# STM32U366 register map
File version: 1.0
CPU: CM33 r0p1, little endian, MPU, FPU, 4 interrupt priority bits
Registers are 32-bit, read-write, reset 0x0 unless marked. A register's access mark holds for its fields unless they carry their own. Offsets are from the block's base; [hi:lo] are bit positions; 'fields as' and 'values as' point back to an identical list.

## LPUART — LPUART address block description
Base 0x40042400
Same registers: SEC_LPUART 0x50042400
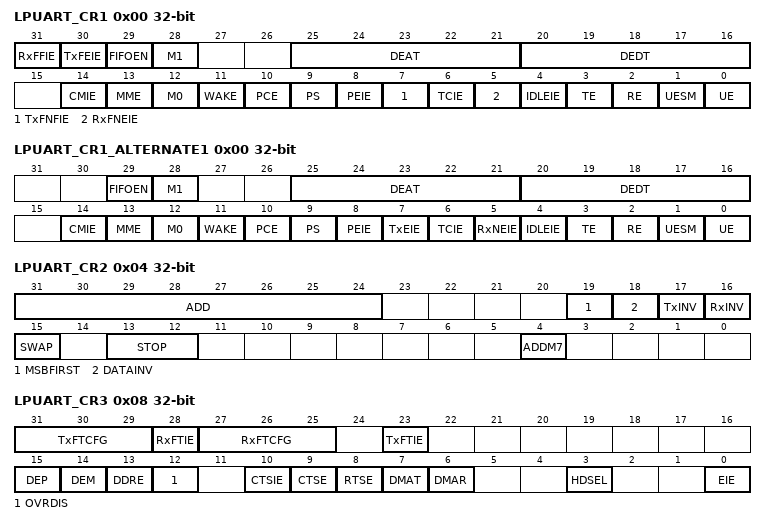
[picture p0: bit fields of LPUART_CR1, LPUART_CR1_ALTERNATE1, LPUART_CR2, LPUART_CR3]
0x00 LPUART_CR1 — LPUART control register 1
  [31] RxFFIE — RxFIFO Full interrupt enable
    0=Interrupt is inhibited; 1=An LPUART interrupt is generated when RxFF=1 in the LPUART_ISR register
  [30] TxFEIE — TxFIFO empty interrupt enable
    0=Interrupt is inhibited; 1=An LPUART interrupt is generated when TxFE=1 in the LPUART_ISR register
  [29] FIFOEN — FIFO mode enable
    0=FIFO mode is disabled; 1=FIFO mode is enabled
  [28] M1 — Word length
  [25:21] DEAT — Driver Enable assertion time
  [20:16] DEDT — Driver Enable deassertion time
  [14] CMIE — Character match interrupt enable
    0=Interrupt is inhibited; 1=A LPUART interrupt is generated when the CMF bit is set in the LPUART_ISR register
  [13] MME — Mute mode enable
    0=Receiver in active mode permanently; 1=Receiver can switch between mute mode and active mode
  [12] M0 — Word length
  [11] WAKE — Receiver wake-up method
    0=Idle line; 1=Address mark
  [10] PCE — Parity control enable
    0=Parity control disabled; 1=Parity control enabled
  [9] PS — Parity selection
    0=Even parity; 1=Odd parity
  [8] PEIE — PE interrupt enable
    0=Interrupt is inhibited; 1=An LPUART interrupt is generated whenever PE=1 in the LPUART_ISR register
  [7] TxFNFIE — TxFIFO not full interrupt enable
    0=Interrupt is inhibited; 1=A LPUART interrupt is generated whenever TxFNF =1 in the LPUART_ISR register
  [6] TCIE — Transmission complete interrupt enable
    0=Interrupt is inhibited; 1=An LPUART interrupt is generated whenever TC=1 in the LPUART_ISR register
  [5] RxFNEIE — RxFIFO not empty interrupt enable
    0=Interrupt is inhibited; 1=A LPUART interrupt is generated whenever ORE=1 or RxFNE=1 in the LPUART_ISR register
  [4] IDLEIE — IDLE interrupt enable
    0=Interrupt is inhibited; 1=An LPUART interrupt is generated whenever IDLE=1 in the LPUART_ISR register
  [3] TE — Transmitter enable
    0=Transmitter is disabled; 1=Transmitter is enabled
  [2] RE — Receiver enable
    0=Receiver is disabled; 1=Receiver is enabled and begins searching for a start bit
  [1] UESM — LPUART enable in low-power mode
    0=LPUART not functional in low-power mode; 1=LPUART functional in low-power mode
  [0] UE — LPUART enable
    0=LPUART prescaler and outputs disabled, low-power mode; 1=LPUART enabled
0x00 LPUART_CR1_ALTERNATE1 (alternate view of LPUART_CR1) — LPUART control register 1
  [29] FIFOEN — FIFO mode enable
    0=FIFO mode is disabled; 1=FIFO mode is enabled
  [28] M1 — Word length
  [25:21] DEAT — Driver Enable assertion time
  [20:16] DEDT — Driver Enable deassertion time
  [14] CMIE — Character match interrupt enable
    values as LPUART_CR1.CMIE
  [13] MME — Mute mode enable
    values as LPUART_CR1.MME
  [12] M0 — Word length
  [11] WAKE — Receiver wake-up method
    0=Idle line; 1=Address mark
  [10] PCE — Parity control enable
    0=Parity control disabled; 1=Parity control enabled
  [9] PS — Parity selection
    0=Even parity; 1=Odd parity
  [8] PEIE — PE interrupt enable
    values as LPUART_CR1.PEIE
  [7] TxEIE — Transmit data register empty
    0=Interrupt is inhibited; 1=A LPUART interrupt is generated whenever TxE =1 in the LPUART_ISR register
  [6] TCIE — Transmission complete interrupt enable
    values as LPUART_CR1.TCIE
  [5] RxNEIE — Receive data register not empty
    0=Interrupt is inhibited; 1=A LPUART interrupt is generated whenever ORE=1 or RxNE=1 in the LPUART_ISR register
  [4] IDLEIE — IDLE interrupt enable
    values as LPUART_CR1.IDLEIE
  [3] TE — Transmitter enable
    0=Transmitter is disabled; 1=Transmitter is enabled
  [2] RE — Receiver enable
    values as LPUART_CR1.RE
  [1] UESM — LPUART enable in low-power mode
    values as LPUART_CR1.UESM
  [0] UE — LPUART enable
    values as LPUART_CR1.UE
0x04 LPUART_CR2 — LPUART control register 2
  [31:24] ADD — Address of the LPUART node
  [19] MSBFIRST — Most significant bit first
    0=data is transmitted/received with data bit 0 first, following the start bit; 1=data is transmitted/received with the MSB (bit 7/8) first, following the start bit
  [18] DATAINV — Binary data inversion
    0=Logical data from the data register are send/received in positive/direct logic; 1=Logical data from the data register are send/received in negative/inverse logic
  [17] TxINV — Tx pin active level inversion
    0=Tx pin signal works using the standard logic levels (Vless thansub>DDless than/sub>=1/idle, Gnd=0/mark); 1=Tx pin signal values are inverted
  [16] RxINV — Rx pin active level inversion
    0=Rx pin signal works using the standard logic levels (Vless thansub>DDless than/sub>=1/idle, Gnd=0/mark); 1=Rx pin signal values are inverted
  [15] SWAP — Swap Tx/Rx pins
    0=Tx/Rx pins are used as defined in standard pinout; 1=The Tx and Rx pins functions are swapped
  [13:12] STOP — Stop bits
    0=1 stop bit; 2=2 stop bits
  [4] ADDM7 — 7-bit Address Detection/4-bit Address Detection
    0=4-bit address detection; 1=7-bit address detection (in 8-bit data mode)
0x08 LPUART_CR3 — LPUART control register 3
  [31:29] TxFTCFG — TxFIFO threshold configuration
    0=TxFIFO reaches 1/8 of its depth; 1=TxFIFO reaches 1/4 of its depth; 6=TxFIFO reaches 1/2 of its depth; 3=TxFIFO reaches 3/4 of its depth; 4=TxFIFO reaches 7/8 of its depth; 5=TxFIFO becomes empty
  [28] RxFTIE — RxFIFO threshold interrupt enable
    0=Interrupt is inhibited; 1=An LPUART interrupt is generated when Receive FIFO reaches the threshold programmed in RxFTCFG[2:0]
  [27:25] RxFTCFG — Receive FIFO threshold configuration
    0=Receive FIFO reaches 1/8 of its depth; 1=Receive FIFO reaches 1/4 of its depth; 6=Receive FIFO reaches 1/2 of its depth; 3=Receive FIFO reaches 3/4 of its depth; 4=Receive FIFO reaches 7/8 of its depth; 5=Receive FIFO becomes full
  [23] TxFTIE — TxFIFO threshold interrupt enable
    0=Interrupt is inhibited; 1=A LPUART interrupt is generated when TxFIFO reaches the threshold programmed in TxFTCFG[2:0]
  [15] DEP — Driver enable polarity selection
    0=DE signal is active high; 1=DE signal is active low
  [14] DEM — Driver enable mode
    0=DE function is disabled; 1=DE function is enabled
  [13] DDRE — DMA Disable on reception Error
    0=DMA is not disabled in case of reception error; 1=DMA is disabled following a reception error
  [12] OVRDIS — Overrun Disable
    0=Overrun Error Flag, ORE is set when received data is not read before receiving new data; 1=Overrun functionality is disabled
  [10] CTSIE — CTS interrupt enable
    0=Interrupt is inhibited; 1=An interrupt is generated whenever CTSIF=1 in the LPUART_ISR register
  [9] CTSE — CTS enable
    0=CTS hardware flow control disabled; 1=CTS mode enabled, data is only transmitted when the CTS input is deasserted (tied to 0)
  [8] RTSE — RTS enable
    0=RTS hardware flow control disabled; 1=RTS output enabled, data is only requested when there is space in the receive buffer
  [7] DMAT — DMA enable transmitter
    1=DMA mode is enabled for transmission; 0=DMA mode is disabled for transmission
  [6] DMAR — DMA enable receiver
    1=DMA mode is enabled for reception; 0=DMA mode is disabled for reception
  [3] HDSEL — Half-duplex selection
    0=Half-duplex mode is not selected; 1=Half-duplex mode is selected
  [0] EIE — Error interrupt enable
    0=Interrupt is inhibited; 1=An interrupt is generated when FE=1 or ORE=1 or NE=1 in the LPUART_ISR register
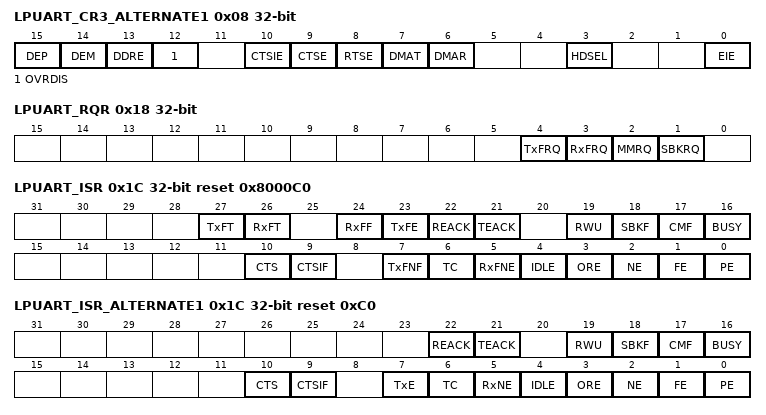
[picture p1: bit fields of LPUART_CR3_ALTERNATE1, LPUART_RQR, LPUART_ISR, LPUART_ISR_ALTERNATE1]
0x08 LPUART_CR3_ALTERNATE1 (alternate view of LPUART_CR3) — LPUART control register 3
  [15] DEP — Driver enable polarity selection
    0=DE signal is active high; 1=DE signal is active low
  [14] DEM — Driver enable mode
    0=DE function is disabled; 1=DE function is enabled
  [13] DDRE — DMA Disable on reception Error
    values as LPUART_CR3.DDRE
  [12] OVRDIS — Overrun Disable
    values as LPUART_CR3.OVRDIS
  [10] CTSIE — CTS interrupt enable
    values as LPUART_CR3.CTSIE
  [9] CTSE — CTS enable
    values as LPUART_CR3.CTSE
  [8] RTSE — RTS enable
    values as LPUART_CR3.RTSE
  [7] DMAT — DMA enable transmitter
    values as LPUART_CR3.DMAT
  [6] DMAR — DMA enable receiver
    values as LPUART_CR3.DMAR
  [3] HDSEL — Half-duplex selection
    values as LPUART_CR3.HDSEL
  [0] EIE — Error interrupt enable
    values as LPUART_CR3.EIE
0x0C LPUART_BRR — LPUART baud rate register
  [19:0] BRR — LPUART baud rate division (LPUARTDIV)
0x18 LPUART_RQR wo — LPUART request register
  [4] TxFRQ — Transmit data flush request
  [3] RxFRQ — Receive data flush request
  [2] MMRQ — Mute mode request
  [1] SBKRQ — Send break request
0x1C LPUART_ISR ro reset 0x8000C0 — LPUART interrupt and status register
  [27] TxFT — TxFIFO threshold flag
    0=TxFIFO does not reach the programmed threshold; 1=TxFIFO reached the programmed threshold
  [26] RxFT — RxFIFO threshold flag
    0=Receive FIFO does not reach the programmed threshold; 1=Receive FIFO reached the programmed threshold
  [24] RxFF — RxFIFO Full
    0=RxFIFO is not Full; 1=RxFIFO is Full
  [23] TxFE — TxFIFO Empty
    0=TxFIFO is not empty; 1=TxFIFO is empty
  [22] REACK — Receive enable acknowledge flag
  [21] TEACK — Transmit enable acknowledge flag
  [19] RWU — Receiver wake-up from mute mode
    0=Receiver in active mode; 1=Receiver in mute mode
  [18] SBKF — Send break flag
    0=No break character transmitted; 1=Break character transmitted
  [17] CMF — Character match flag
    0=No Character match detected; 1=Character match detected
  [16] BUSY — Busy flag
    0=LPUART is idle (no reception); 1=reception ongoing
  [10] CTS — CTS flag
    0=CTS line set; 1=CTS line reset
  [9] CTSIF — CTS interrupt flag
    0=No change occurred on the CTS status line; 1=A change occurred on the CTS status line
  [7] TxFNF — TxFIFO not full
    0=Data register is full/Transmit FIFO is full; 1=Data register/Transmit FIFO is not full
  [6] TC — Transmission complete
  [5] RxFNE — RxFIFO not empty
    0=Data is not received; 1=Received data is ready to be read
  [4] IDLE — Idle line detected
    0=No Idle line is detected; 1=Idle line is detected
  [3] ORE — Overrun error
    1=Overrun error is detected
  [2] NE — Start bit noise detection flag
    0=No noise is detected; 1=Noise is detected
  [1] FE — Framing error
    0=No Framing error is detected; 1=Framing error or break character is detected
  [0] PE — Parity error
    0=No parity error; 1=Parity error
0x1C LPUART_ISR_ALTERNATE1 ro reset 0xC0 (alternate view of LPUART_ISR) — LPUART interrupt and status register
  [22] REACK — Receive enable acknowledge flag
  [21] TEACK — Transmit enable acknowledge flag
  [19] RWU — Receiver wake-up from mute mode
    0=Receiver in active mode; 1=Receiver in mute mode
  [18] SBKF — Send break flag
    values as LPUART_ISR.SBKF
  [17] CMF — Character match flag
    0=No Character match detected; 1=Character match detected
  [16] BUSY — Busy flag
    0=LPUART is idle (no reception); 1=Reception ongoing
  [10] CTS — CTS flag
    0=CTS line set; 1=CTS line reset
  [9] CTSIF — CTS interrupt flag
    values as LPUART_ISR.CTSIF
  [7] TxE — Transmit data register empty
    0=Data register full; 1=Data register empty
  [6] TC — Transmission complete
  [5] RxNE — Read data register not empty
    0=Data is not received; 1=Received data is ready to be read
  [4] IDLE — Idle line detected
    0=No Idle line is detected; 1=Idle line is detected
  [3] ORE — Overrun error
    1=Overrun error is detected
  [2] NE — Start bit noise detection flag
    0=No noise is detected; 1=Noise is detected
  [1] FE — Framing error
    values as LPUART_ISR.FE
  [0] PE — Parity error
    0=No parity error; 1=Parity error
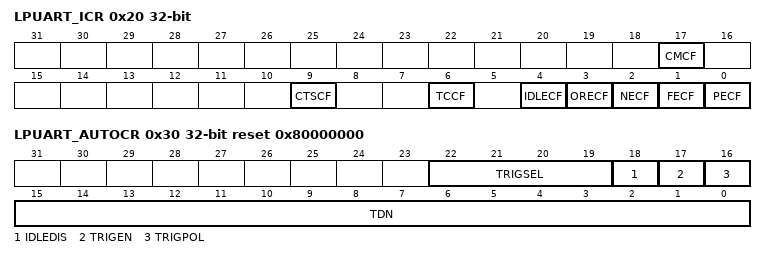
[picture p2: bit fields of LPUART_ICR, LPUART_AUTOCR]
0x20 LPUART_ICR wo — LPUART interrupt flag clear register
  [17] CMCF — Character match clear flag
  [9] CTSCF — CTS clear flag
  [6] TCCF — Transmission complete clear flag
  [4] IDLECF — Idle line detected clear flag
  [3] ORECF — Overrun error clear flag
  [2] NECF — Noise detected clear flag
  [1] FECF — Framing error clear flag
  [0] PECF — Parity error clear flag
0x24 LPUART_RDR ro — LPUART receive data register
  [8:0] RDR — Receive data value
0x28 LPUART_TDR — LPUART transmit data register
  [8:0] TDR — Transmit data value
0x2C LPUART_PRESC — LPUART prescaler register
  [3:0] PRESCALER — Clock prescaler
    0=input clock not divided; 1=input clock divided by 2; 2=input clock divided by 4; 3=input clock divided by 6; 4=input clock divided by 8; 5=input clock divided by 10; 6=input clock divided by 12; 7=input clock divided by 16; 8=input clock divided by 32; 9=input clock divided by 64; 10=input clock divided by 128; 11=input clock divided by 256
0x30 LPUART_AUTOCR reset 0x80000000 — LPUART autonomous mode control register
  [22:19] TRIGSEL — Trigger selection bits
    0=lpuart_trg0 selected; 1=lpuart_trg1 selected; 15=lpuart_trg15 selected
  [18] IDLEDIS — Idle frame transmission disable bit after enabling the transmitter
    0=Idle frame sent after enabling the transmitter (TE = 1 in LPUART_CR1); 1=Idle frame not sent after enabling the transmitter
  [17] TRIGEN — Trigger enable bit
    0=Trigger disabled; 1=Trigger enabled
  [16] TRIGPOL — Trigger polarity bit
    0=Trigger active on rising edge; 1=Trigger active on falling edge
  [15:0] TDN — TDC transmission data number
